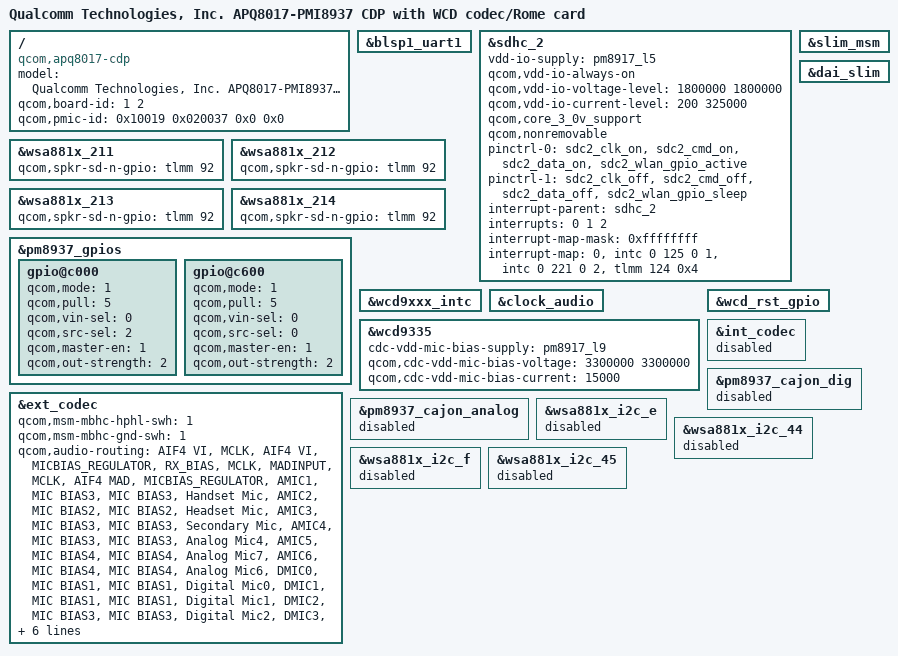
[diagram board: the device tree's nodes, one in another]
/*
 * Copyright (c) 2016, The Linux Foundation. All rights reserved.
 *
 * This program is free software; you can redistribute it and/or modify
 * it under the terms of the GNU General Public License version 2 and
 * only version 2 as published by the Free Software Foundation.
 *
 * This program is distributed in the hope that it will be useful,
 * but WITHOUT ANY WARRANTY; without even the implied warranty of
 * MERCHANTABILITY or FITNESS FOR A PARTICULAR PURPOSE.  See the
 * GNU General Public License for more details.
 */

/dts-v1/;

#include "apq8017.dtsi"
#include "msm8917-pmi8937-cdp.dtsi"

/ {
	model = "Qualcomm Technologies, Inc. APQ8017-PMI8937 CDP \
						with WCD codec/Rome card";
	compatible = "qcom,apq8017-cdp", "qcom,apq8017", "qcom,cdp";
	qcom,board-id= <1 2>;
	qcom,pmic-id = <0x10019 0x020037 0x0 0x0>;
};

&blsp1_uart1 {
	status = "ok";
};

&sdhc_2 {
	/* device core power supply */
	/delete-property/vdd-supply;
	/delete-property/qcom,vdd-voltage-level;
	/delete-property/qcom,vdd-current-level;

	/* device communication power supply */
	vdd-io-supply = <&pm8917_l5>;
	qcom,vdd-io-always-on;
	qcom,vdd-io-voltage-level = <1800000 1800000>;
	qcom,vdd-io-current-level = <200 325000>;

	qcom,core_3_0v_support;
	qcom,nonremovable;

	pinctrl-names = "active", "sleep";
	pinctrl-0 = <&sdc2_clk_on &sdc2_cmd_on &sdc2_data_on
			&sdc2_wlan_gpio_active>;
	pinctrl-1 = <&sdc2_clk_off &sdc2_cmd_off &sdc2_data_off
			&sdc2_wlan_gpio_sleep>;

	#address-cells = <0>;
	interrupt-parent = <&sdhc_2>;
	interrupts = <0 1 2>;
	#interrupt-cells = <1>;
	interrupt-map-mask = <0xffffffff>;
	interrupt-map = <0 &intc 0 125 0
		1 &intc 0 221 0
		2 &tlmm 124 0x4>;
	interrupt-names = "hc_irq", "pwr_irq", "sdiowakeup_irq";

	/delete-property/cd-gpios;
	/delete-property/qcom,devfreq,freq-table;

	status = "ok";

};

&wsa881x_211 {
	qcom,spkr-sd-n-gpio = <&tlmm 92 0>;
};

&wsa881x_212 {
	qcom,spkr-sd-n-gpio = <&tlmm 92 0>;
};

&wsa881x_213 {
	qcom,spkr-sd-n-gpio = <&tlmm 92 0>;
};

&wsa881x_214 {
	qcom,spkr-sd-n-gpio = <&tlmm 92 0>;
};

&pm8937_gpios {
	gpio@c000 {
		status = "ok";
		qcom,mode = <1>;
		qcom,pull = <5>;
		qcom,vin-sel = <0>;
		qcom,src-sel = <2>;
		qcom,master-en = <1>;
		qcom,out-strength = <2>;
	};

	gpio@c600 {
		status = "ok";
		qcom,mode = <1>;
		qcom,pull = <5>;
		qcom,vin-sel = <0>;
		qcom,src-sel = <0>;
		qcom,master-en = <1>;
		qcom,out-strength = <2>;
	};
};

&slim_msm {
	status = "okay";
};

&dai_slim {
	status = "okay";
};

&wcd9xxx_intc {
	status = "okay";
};

&clock_audio {
	status = "okay";
};

&wcd9335 {
	status = "okay";
	cdc-vdd-mic-bias-supply = <&pm8917_l9>;
	qcom,cdc-vdd-mic-bias-voltage = <3300000 3300000>;
	qcom,cdc-vdd-mic-bias-current = <15000>;
};

&wcd_rst_gpio {
	status = "okay";
};

&ext_codec {
	status = "okay";
	qcom,msm-mbhc-hphl-swh = <1>;
	qcom,msm-mbhc-gnd-swh = <1>;
	qcom,audio-routing =
		"AIF4 VI", "MCLK",
		"AIF4 VI", "MICBIAS_REGULATOR",
		"RX_BIAS", "MCLK",
		"MADINPUT", "MCLK",
		"AIF4 MAD", "MICBIAS_REGULATOR",
		"AMIC1", "MIC BIAS3",
		"MIC BIAS3", "Handset Mic",
		"AMIC2", "MIC BIAS2",
		"MIC BIAS2", "Headset Mic",
		"AMIC3", "MIC BIAS3",
		"MIC BIAS3", "Secondary Mic",
		"AMIC4", "MIC BIAS3",
		"MIC BIAS3", "Analog Mic4",
		"AMIC5", "MIC BIAS4",
		"MIC BIAS4", "Analog Mic7",
		"AMIC6", "MIC BIAS4",
		"MIC BIAS4", "Analog Mic6",
		"DMIC0", "MIC BIAS1",
		"MIC BIAS1", "Digital Mic0",
		"DMIC1", "MIC BIAS1",
		"MIC BIAS1", "Digital Mic1",
		"DMIC2", "MIC BIAS3",
		"MIC BIAS3", "Digital Mic2",
		"DMIC3", "MIC BIAS3",
		"MIC BIAS3", "Digital Mic3",
		"DMIC4", "MIC BIAS4",
		"MIC BIAS4", "Digital Mic4",
		"DMIC5", "MIC BIAS4",
		"MIC BIAS4", "Digital Mic5",
		"MIC BIAS3", "MICBIAS_REGULATOR",
		"MIC BIAS4", "MICBIAS_REGULATOR",
		"SpkrLeft IN", "SPK1 OUT",
		"SpkrRight IN", "SPK2 OUT";

};

&int_codec {
	status = "disabled";
};

&pm8937_cajon_dig {
	status = "disabled";
};

&pm8937_cajon_analog {
	status = "disabled";
};

&wsa881x_i2c_e {
	status = "disabled";
};

&wsa881x_i2c_44 {
	status = "disabled";
};

&wsa881x_i2c_f {
	status = "disabled";
};

&wsa881x_i2c_45 {
	status = "disabled";
};
